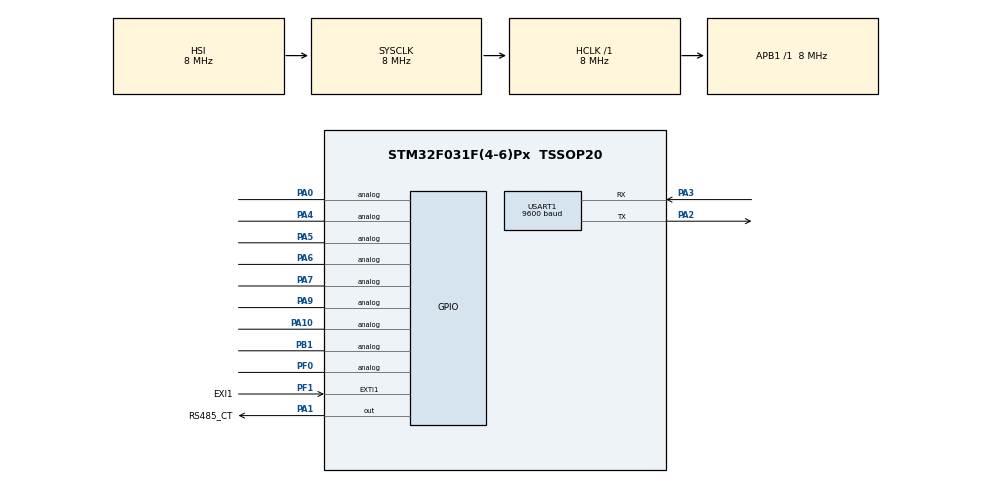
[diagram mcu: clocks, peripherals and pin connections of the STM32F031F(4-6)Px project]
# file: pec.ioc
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IWDG.Prescaler=IWDG_PRESCALER_16
IWDG.Reload=625
IWDG.Window=625
Mcu.Family=STM32F0
Mcu.Name=STM32F031F(4-6)Px
Mcu.Package=TSSOP20
NVIC.EXTI0_1_IRQn=true\:3\:0\:true\:false\:true\:true\:true\:true
NVIC.TIM2_IRQn=true\:3\:0\:true\:false\:true\:true\:true\:true
NVIC.USART1_IRQn=true\:3\:0\:true\:false\:true\:true\:true\:true
PA0.Signal=GPIO_Analog
PA1.GPIO_Label=RS485_CT
PA1.Signal=GPIO_Output
PA10.Signal=GPIO_Analog
PA13.Mode=Serial_Wire
PA13.Signal=SYS_SWDIO
PA14.Mode=Serial_Wire
PA14.Signal=SYS_SWCLK
PA2.Mode=Asynchronous
PA2.Signal=USART1_TX
PA3.Mode=Asynchronous
PA3.Signal=USART1_RX
PA4.Signal=GPIO_Analog
PA5.Signal=GPIO_Analog
PA6.Signal=GPIO_Analog
PA7.Signal=GPIO_Analog
PA9.Signal=GPIO_Analog
PB1.Signal=GPIO_Analog
PF0-OSC_IN.Signal=GPIO_Analog
PF1-OSC_OUT.GPIO_Label=EXI1
PF1-OSC_OUT.GPIO_ModeDefaultEXTI=GPIO_MODE_IT_RISING_FALLING
PF1-OSC_OUT.Signal=GPXTI1
ProjectManager.HeapSize=0x200
ProjectManager.StackSize=0x400
ProjectManager.TargetToolchain=STM32CubeIDE
RCC.AHBFreq_Value=8000000
RCC.APB1Freq_Value=8000000
RCC.APB1TimFreq_Value=8000000
RCC.HCLKFreq_Value=8000000
RCC.SYSCLKFreq_VALUE=8000000
TIM2.AutoReloadPreload=TIM_AUTORELOAD_PRELOAD_ENABLE
TIM2.Period=65535
USART1.BaudRate=9600
USART1.VirtualMode-Asynchronous=VM_ASYNC
VP_IWDG_VS_IWDG.Mode=IWDG_Activate
VP_TIM2_VS_ClockSourceINT.Mode=Internal
board=custom

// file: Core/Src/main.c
/* USER CODE BEGIN Header */
/**
  ******************************************************************************
  * @file           : main.c
  * @brief          : Main program body
  ******************************************************************************
  * @attention
  *
  * Copyright (c) 2024 STMicroelectronics.
  * All rights reserved.
  *
  * This software is licensed under terms that can be found in the LICENSE file
  * in the root directory of this software component.
  * If no LICENSE file comes with this software, it is provided AS-IS.
  *
  ******************************************************************************
  */
/* USER CODE END Header */
#include "main.h"

IWDG_HandleTypeDef hiwdg;

TIM_HandleTypeDef htim2;

UART_HandleTypeDef huart1;

void SystemClock_Config(void);
static void MX_GPIO_Init(void);
static void MX_USART1_UART_Init(void);
static void MX_TIM2_Init(void);
static void MX_IWDG_Init(void);

int main(void)
{

  /* MCU Configuration--------------------------------------------------------*/

  /* Reset of all peripherals, Initializes the Flash interface and the Systick. */
  HAL_Init();

  /* USER CODE BEGIN Init */
  __enable_irq();
  /* USER CODE END Init */

  /* Configure the system clock */
  SystemClock_Config();

  /* Initialize all configured peripherals */
  MX_GPIO_Init();
  MX_USART1_UART_Init();
  MX_TIM2_Init();
  MX_IWDG_Init();
  /* USER CODE BEGIN 2 */
  extern int app_main( void );
  app_main();
  /* USER CODE END 2 */

  /* Infinite loop */
  while (1)
  {

  }
}

void SystemClock_Config(void)
{
  RCC_OscInitTypeDef RCC_OscInitStruct = {0};
  RCC_ClkInitTypeDef RCC_ClkInitStruct = {0};
  RCC_PeriphCLKInitTypeDef PeriphClkInit = {0};

  /** Initializes the RCC Oscillators according to the specified parameters
  * in the RCC_OscInitTypeDef structure.
  */
  RCC_OscInitStruct.OscillatorType = RCC_OSCILLATORTYPE_HSI|RCC_OSCILLATORTYPE_LSI;
  RCC_OscInitStruct.HSIState = RCC_HSI_ON;
  RCC_OscInitStruct.HSICalibrationValue = RCC_HSICALIBRATION_DEFAULT;
  RCC_OscInitStruct.LSIState = RCC_LSI_ON;
  RCC_OscInitStruct.PLL.PLLState = RCC_PLL_NONE;
  if (HAL_RCC_OscConfig(&RCC_OscInitStruct) != HAL_OK)
  {
    Error_Handler();
  }

  /** Initializes the CPU, AHB and APB buses clocks
  */
  RCC_ClkInitStruct.ClockType = RCC_CLOCKTYPE_HCLK|RCC_CLOCKTYPE_SYSCLK
                              |RCC_CLOCKTYPE_PCLK1;
  RCC_ClkInitStruct.SYSCLKSource = RCC_SYSCLKSOURCE_HSI;
  RCC_ClkInitStruct.AHBCLKDivider = RCC_SYSCLK_DIV1;
  RCC_ClkInitStruct.APB1CLKDivider = RCC_HCLK_DIV1;

  if (HAL_RCC_ClockConfig(&RCC_ClkInitStruct, FLASH_LATENCY_0) != HAL_OK)
  {
    Error_Handler();
  }
  PeriphClkInit.PeriphClockSelection = RCC_PERIPHCLK_USART1;
  PeriphClkInit.Usart1ClockSelection = RCC_USART1CLKSOURCE_PCLK1;
  if (HAL_RCCEx_PeriphCLKConfig(&PeriphClkInit) != HAL_OK)
  {
    Error_Handler();
  }
}

static void MX_IWDG_Init(void)
{

  hiwdg.Instance = IWDG;
  hiwdg.Init.Prescaler = IWDG_PRESCALER_16;
  hiwdg.Init.Window = 625;
  hiwdg.Init.Reload = 625;
  if (HAL_IWDG_Init(&hiwdg) != HAL_OK)
  {
    Error_Handler();
  }

}

static void MX_TIM2_Init(void)
{

  TIM_ClockConfigTypeDef sClockSourceConfig = {0};
  TIM_MasterConfigTypeDef sMasterConfig = {0};

  htim2.Instance = TIM2;
  htim2.Init.Prescaler = 0;
  htim2.Init.CounterMode = TIM_COUNTERMODE_UP;
  htim2.Init.Period = 65535;
  htim2.Init.ClockDivision = TIM_CLOCKDIVISION_DIV1;
  htim2.Init.AutoReloadPreload = TIM_AUTORELOAD_PRELOAD_ENABLE;
  if (HAL_TIM_Base_Init(&htim2) != HAL_OK)
  {
    Error_Handler();
  }
  sClockSourceConfig.ClockSource = TIM_CLOCKSOURCE_INTERNAL;
  if (HAL_TIM_ConfigClockSource(&htim2, &sClockSourceConfig) != HAL_OK)
  {
    Error_Handler();
  }
  sMasterConfig.MasterOutputTrigger = TIM_TRGO_RESET;
  sMasterConfig.MasterSlaveMode = TIM_MASTERSLAVEMODE_DISABLE;
  if (HAL_TIMEx_MasterConfigSynchronization(&htim2, &sMasterConfig) != HAL_OK)
  {
    Error_Handler();
  }

}

static void MX_USART1_UART_Init(void)
{

  huart1.Instance = USART1;
  huart1.Init.BaudRate = 9600;
  huart1.Init.WordLength = UART_WORDLENGTH_8B;
  huart1.Init.StopBits = UART_STOPBITS_1;
  huart1.Init.Parity = UART_PARITY_NONE;
  huart1.Init.Mode = UART_MODE_TX_RX;
  huart1.Init.HwFlowCtl = UART_HWCONTROL_NONE;
  huart1.Init.OverSampling = UART_OVERSAMPLING_16;
  huart1.Init.OneBitSampling = UART_ONE_BIT_SAMPLE_DISABLE;
  huart1.AdvancedInit.AdvFeatureInit = UART_ADVFEATURE_NO_INIT;
  if (HAL_UART_Init(&huart1) != HAL_OK)
  {
    Error_Handler();
  }

}

static void MX_GPIO_Init(void)
{
  GPIO_InitTypeDef GPIO_InitStruct = {0};

  /* GPIO Ports Clock Enable */
  __HAL_RCC_GPIOF_CLK_ENABLE();
  __HAL_RCC_GPIOA_CLK_ENABLE();
  __HAL_RCC_GPIOB_CLK_ENABLE();

  /*Configure GPIO pin Output Level */
  HAL_GPIO_WritePin(RS485_CT_GPIO_Port, RS485_CT_Pin, GPIO_PIN_RESET);

  /*Configure GPIO pin : PF0 */
  GPIO_InitStruct.Pin = GPIO_PIN_0;
  GPIO_InitStruct.Mode = GPIO_MODE_ANALOG;
  GPIO_InitStruct.Pull = GPIO_NOPULL;
  HAL_GPIO_Init(GPIOF, &GPIO_InitStruct);

  /*Configure GPIO pin : EXI1_Pin */
  GPIO_InitStruct.Pin = EXI1_Pin;
  GPIO_InitStruct.Mode = GPIO_MODE_IT_RISING_FALLING;
  GPIO_InitStruct.Pull = GPIO_NOPULL;
  HAL_GPIO_Init(EXI1_GPIO_Port, &GPIO_InitStruct);

  /*Configure GPIO pins : PA0 PA4 PA5 PA6
                           PA7 PA9 PA10 */
  GPIO_InitStruct.Pin = GPIO_PIN_0|GPIO_PIN_4|GPIO_PIN_5|GPIO_PIN_6
                          |GPIO_PIN_7|GPIO_PIN_9|GPIO_PIN_10;
  GPIO_InitStruct.Mode = GPIO_MODE_ANALOG;
  GPIO_InitStruct.Pull = GPIO_NOPULL;
  HAL_GPIO_Init(GPIOA, &GPIO_InitStruct);

  /*Configure GPIO pin : RS485_CT_Pin */
  GPIO_InitStruct.Pin = RS485_CT_Pin;
  GPIO_InitStruct.Mode = GPIO_MODE_OUTPUT_PP;
  GPIO_InitStruct.Pull = GPIO_NOPULL;
  GPIO_InitStruct.Speed = GPIO_SPEED_FREQ_LOW;
  HAL_GPIO_Init(RS485_CT_GPIO_Port, &GPIO_InitStruct);

  /*Configure GPIO pin : PB1 */
  GPIO_InitStruct.Pin = GPIO_PIN_1;
  GPIO_InitStruct.Mode = GPIO_MODE_ANALOG;
  GPIO_InitStruct.Pull = GPIO_NOPULL;
  HAL_GPIO_Init(GPIOB, &GPIO_InitStruct);

  /* EXTI interrupt init*/
  HAL_NVIC_SetPriority(EXTI0_1_IRQn, 3, 0);
  HAL_NVIC_EnableIRQ(EXTI0_1_IRQn);

}

void Error_Handler(void)
{
  __disable_irq();
  while (1)
  {
  }
}
